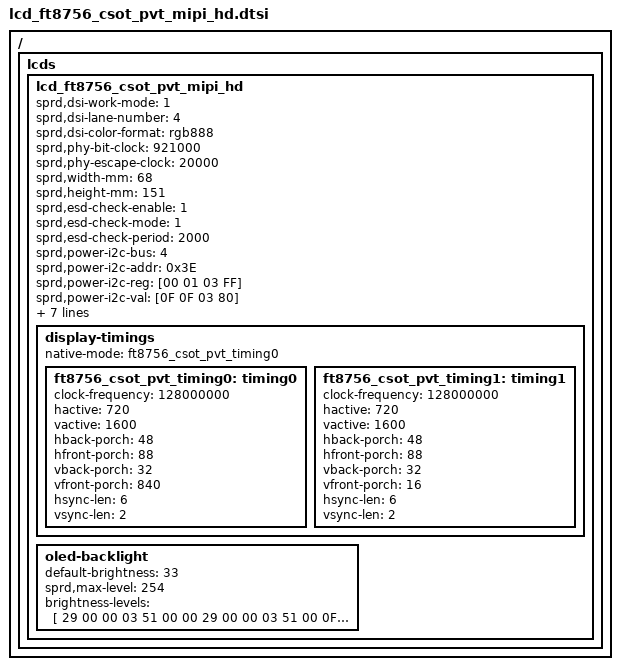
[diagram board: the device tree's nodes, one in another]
/*
 * ft8756 csot HD Scaling-Up LCD config dtsi file for spreadtrum
 *
 * Copyright (C) 2018, Spreadtrum Communications Inc.
 *
 * SPDX-License-Identifier: (GPL-2.0+ OR MIT)
 */

/ {
	fragment {
		target-path = "/";
		__overlay__ {
			lcds {
				lcd_ft8756_csot_pvt_mipi_hd: lcd_ft8756_csot_pvt_mipi_hd {

					sprd,dsi-work-mode = <1>; /* video burst mode*/
					sprd,dsi-lane-number = <4>;
					sprd,dsi-color-format = "rgb888";

					sprd,phy-bit-clock = <921000>;	/* kbps */
					sprd,phy-escape-clock = <20000>;/* kHz */

					sprd,width-mm = <68>;
					sprd,height-mm = <151>;

					sprd,esd-check-enable = <1>;
					sprd,esd-check-mode = <1>;
					sprd,esd-check-period = <2000>;
					//sprd,esd-check-register = <0xA>;
					//sprd,esd-check-value = <0x9c>;

					sprd,power-i2c-bus = <4>;
					sprd,power-i2c-addr = <0x3E>;
					/*sprd,power-i2c-speed = <400000>;*/
					sprd,power-i2c-reg = [00 01 03 FF];
					sprd,power-i2c-val = [0F 0F 03 80];

					sprd,reset-on-sequence = <1 10>, <0 10>, <1 35>;
					sprd,reset-off-sequence = <1 10>;

					//sprd,use-dcs-write;
					sprd,ft-type;

					sprd,initial-command = [
						29 01 00 02 00 00 
						29 01 00 04 FF 87 56 01 
						29 01 00 02 00 80 
						29 01 00 03 FF 87 56 
						29 01 00 02 00 B0 
						29 01 00 04 CA 00 00 0C 
						29 00 00 02 00 B5
						29 00 00 02 CA 03
						29 01 00 02 00 00 
						29 01 00 04 FF FF FF FF 
						13 00 00 02 35 00
						29 00 00 03 51 00 00
						29 00 00 02 53 2C
						29 00 00 02 55 01
						03 FA 00 01 11
						03 14 00 01 29
						];

					sprd,sleep-in-command = [
						03 32 00 01 28
						03 96 00 01 10
						29 00 00 02 00 00 
						29 00 00 04 FF 87 56 01 
						29 00 00 02 00 80 
						29 00 00 03 FF 87 56 
						29 00 00 02 00 00 
						29 96 00 05 F7 5A A5 95 27
						];

					display-timings {
						native-mode = <&ft8756_csot_pvt_timing0>;

						ft8756_csot_pvt_timing0: timing0 {
							clock-frequency = <128000000>;
							hactive = <720>;
							vactive = <1600>;
							hback-porch = <48>;
							hfront-porch = <88>;
							vback-porch = <32>;
							vfront-porch = <840>;
							hsync-len = <6>;
							vsync-len = <2>;
						};

						ft8756_csot_pvt_timing1: timing1 {
							clock-frequency = <128000000>;
							hactive = <720>;
							vactive = <1600>;
							hback-porch = <48>;
							hfront-porch = <88>;
							vback-porch = <32>;
							vfront-porch = <16>;
							hsync-len = <6>;
							vsync-len = <2>;
						};
					};

					oled-backlight {			
						default-brightness = <33>;	
						sprd,max-level = <254>;
						brightness-levels = [
            		    	29 00 00 03 51 00 00
							29 00 00 03 51 00 0F
							29 00 00 03 51 01 05
							29 00 00 03 51 01 0A
							29 00 00 03 51 02 05
							29 00 00 03 51 03 00
							29 00 00 03 51 03 0B
							29 00 00 03 51 04 06
							29 00 00 03 51 05 01
							29 00 00 03 51 05 0C
							29 00 00 03 51 06 07
							29 00 00 03 51 07 02
							29 00 00 03 51 07 0D
							29 00 00 03 51 08 08
							29 00 00 03 51 09 03
							29 00 00 03 51 09 0F
							29 00 00 03 51 0A 0A
							29 00 00 03 51 0B 05
							29 00 00 03 51 0C 00
							29 00 00 03 51 0C 0B
							29 00 00 03 51 0D 06
							29 00 00 03 51 0E 01
							29 00 00 03 51 0E 0C
							29 00 00 03 51 0F 07
							29 00 00 03 51 10 02
							29 00 00 03 51 10 0D
							29 00 00 03 51 11 08
							29 00 00 03 51 12 03
							29 00 00 03 51 12 0E
							29 00 00 03 51 13 09
							29 00 00 03 51 14 04
							29 00 00 03 51 14 0F
							29 00 00 03 51 15 0A
							29 00 00 03 51 16 05
							29 00 00 03 51 17 00
							29 00 00 03 51 17 0C
							29 00 00 03 51 18 07
							29 00 00 03 51 19 02
							29 00 00 03 51 19 0D
							29 00 00 03 51 1A 08
							29 00 00 03 51 1B 03
							29 00 00 03 51 1B 0E
							29 00 00 03 51 1C 09
							29 00 00 03 51 1D 04
							29 00 00 03 51 1D 0F
							29 00 00 03 51 1E 0A
							29 00 00 03 51 1F 05
							29 00 00 03 51 20 00
							29 00 00 03 51 20 0B
							29 00 00 03 51 21 06
							29 00 00 03 51 22 01
							29 00 00 03 51 22 0C
							29 00 00 03 51 23 07
							29 00 00 03 51 24 02
							29 00 00 03 51 24 0D
							29 00 00 03 51 25 09
							29 00 00 03 51 26 04
							29 00 00 03 51 26 0F
							29 00 00 03 51 27 0A
							29 00 00 03 51 28 05
							29 00 00 03 51 29 00
							29 00 00 03 51 29 0B
							29 00 00 03 51 2A 06
							29 00 00 03 51 2B 01
							29 00 00 03 51 2B 0C
							29 00 00 03 51 2C 07
							29 00 00 03 51 2D 02
							29 00 00 03 51 2D 0D
							29 00 00 03 51 2E 08
							29 00 00 03 51 2F 03
							29 00 00 03 51 2F 0E
							29 00 00 03 51 30 09
							29 00 00 03 51 31 04
							29 00 00 03 51 31 0F
							29 00 00 03 51 32 0A
							29 00 00 03 51 33 06
							29 00 00 03 51 34 01
							29 00 00 03 51 34 0C
							29 00 00 03 51 35 07
							29 00 00 03 51 36 02
							29 00 00 03 51 36 0D
							29 00 00 03 51 37 08
							29 00 00 03 51 38 03
							29 00 00 03 51 38 0E
							29 00 00 03 51 39 09
							29 00 00 03 51 3A 04
							29 00 00 03 51 3A 0F
							29 00 00 03 51 3B 0A
							29 00 00 03 51 3C 05
							29 00 00 03 51 3D 00
							29 00 00 03 51 3D 0B
							29 00 00 03 51 3E 06
							29 00 00 03 51 3F 01
							29 00 00 03 51 3F 0C
							29 00 00 03 51 40 07
							29 00 00 03 51 41 03
							29 00 00 03 51 41 0E
							29 00 00 03 51 42 09
							29 00 00 03 51 43 04
							29 00 00 03 51 43 0F
							29 00 00 03 51 44 0A
							29 00 00 03 51 45 05
							29 00 00 03 51 46 00
							29 00 00 03 51 46 0B
							29 00 00 03 51 47 06
							29 00 00 03 51 48 01
							29 00 00 03 51 48 0C
							29 00 00 03 51 49 07
							29 00 00 03 51 4A 02
							29 00 00 03 51 4A 0D
							29 00 00 03 51 4B 08
							29 00 00 03 51 4C 03
							29 00 00 03 51 4C 0E
							29 00 00 03 51 4D 09
							29 00 00 03 51 4E 04
							29 00 00 03 51 4F 00
							29 00 00 03 51 4F 0B
							29 00 00 03 51 50 06
							29 00 00 03 51 51 01
							29 00 00 03 51 51 0C
							29 00 00 03 51 52 07
							29 00 00 03 51 53 02
							29 00 00 03 51 53 0D
							29 00 00 03 51 54 08
							29 00 00 03 51 55 03
							29 00 00 03 51 55 0E
							29 00 00 03 51 56 09
							29 00 00 03 51 57 04
							29 00 00 03 51 57 0F
							29 00 00 03 51 58 0A
							29 00 00 03 51 59 05
							29 00 00 03 51 5A 00
							29 00 00 03 51 5A 0B
							29 00 00 03 51 5B 06
							29 00 00 03 51 5C 01
							29 00 00 03 51 5C 0D
							29 00 00 03 51 5D 08
							29 00 00 03 51 5E 03
							29 00 00 03 51 5E 0E
							29 00 00 03 51 5F 09
							29 00 00 03 51 60 04
							29 00 00 03 51 60 0F
							29 00 00 03 51 61 0A
							29 00 00 03 51 62 05
							29 00 00 03 51 63 00
							29 00 00 03 51 63 0B
							29 00 00 03 51 64 06
							29 00 00 03 51 65 01
							29 00 00 03 51 65 0C
							29 00 00 03 51 66 07
							29 00 00 03 51 67 02
							29 00 00 03 51 67 0D
							29 00 00 03 51 68 08
							29 00 00 03 51 69 03
							29 00 00 03 51 69 0E
							29 00 00 03 51 6A 0A
							29 00 00 03 51 6B 05
							29 00 00 03 51 6C 00
							29 00 00 03 51 6C 0B
							29 00 00 03 51 6D 06
							29 00 00 03 51 6E 01
							29 00 00 03 51 6E 0C
							29 00 00 03 51 6F 07
							29 00 00 03 51 70 02
							29 00 00 03 51 70 0D
							29 00 00 03 51 71 08
							29 00 00 03 51 72 03
							29 00 00 03 51 72 0E
							29 00 00 03 51 73 09
							29 00 00 03 51 74 04
							29 00 00 03 51 74 0F
							29 00 00 03 51 75 0A
							29 00 00 03 51 76 05
							29 00 00 03 51 77 00
							29 00 00 03 51 77 0B
							29 00 00 03 51 78 07
							29 00 00 03 51 79 02
							29 00 00 03 51 79 0D
							29 00 00 03 51 7A 08
							29 00 00 03 51 7B 03
							29 00 00 03 51 7B 0E
							29 00 00 03 51 7C 09
							29 00 00 03 51 7D 04
							29 00 00 03 51 7D 0F
							29 00 00 03 51 7E 0A
							29 00 00 03 51 7F 05
							29 00 00 03 51 80 00
							29 00 00 03 51 80 0B
							29 00 00 03 51 81 06
							29 00 00 03 51 82 01
							29 00 00 03 51 82 0C
							29 00 00 03 51 83 07
							29 00 00 03 51 84 02
							29 00 00 03 51 84 0D
							29 00 00 03 51 85 08
							29 00 00 03 51 86 04
							29 00 00 03 51 86 0F
							29 00 00 03 51 87 0A
							29 00 00 03 51 88 05
							29 00 00 03 51 89 00
							29 00 00 03 51 89 0B
							29 00 00 03 51 8A 06
							29 00 00 03 51 8B 01
							29 00 00 03 51 8B 0C
							29 00 00 03 51 8C 07
							29 00 00 03 51 8D 02
							29 00 00 03 51 8D 0D
							29 00 00 03 51 8E 08
							29 00 00 03 51 8F 03
							29 00 00 03 51 8F 0E
							29 00 00 03 51 90 09
							29 00 00 03 51 91 04
							29 00 00 03 51 91 0F
							29 00 00 03 51 92 0A
							29 00 00 03 51 93 05
							29 00 00 03 51 94 01
							29 00 00 03 51 94 0C
							29 00 00 03 51 95 07
							29 00 00 03 51 96 02
							29 00 00 03 51 96 0D
							29 00 00 03 51 97 08
							29 00 00 03 51 98 03
							29 00 00 03 51 98 0E
							29 00 00 03 51 99 09
							29 00 00 03 51 9A 04
							29 00 00 03 51 9A 0F
							29 00 00 03 51 9B 0A
							29 00 00 03 51 9C 05
							29 00 00 03 51 9D 00
							29 00 00 03 51 9D 0B
							29 00 00 03 51 9E 06
							29 00 00 03 51 9F 01
							29 00 00 03 51 9F 0C
							29 00 00 03 51 A0 07
							29 00 00 03 51 A1 02
							29 00 00 03 51 A1 0E
							29 00 00 03 51 A2 09
							29 00 00 03 51 A3 04
							29 00 00 03 51 A3 0F
							29 00 00 03 51 A4 0A
							29 00 00 03 51 A5 05
							29 00 00 03 51 A6 00
							29 00 00 03 51 A6 0B
							29 00 00 03 51 A7 06
							29 00 00 03 51 A8 01
							29 00 00 03 51 A8 0C
							29 00 00 03 51 A9 07
							29 00 00 03 51 AA 02
							29 00 00 03 51 AA 0D
							29 00 00 03 51 AB 08
							29 00 00 03 51 AC 03
							29 00 00 03 51 AC 0E
							29 00 00 03 51 AD 09
							29 00 00 03 51 AE 04
							29 00 00 03 51 AF 00
						];
					};
				};
			};
		};
	};
};
